# STM32C011D6Y6 register map
File version: 1.0
Registers are 32-bit, access not given, reset 0x0 unless marked. A register's access mark holds for its fields unless they carry their own. Offsets are from the block's base; [hi:lo] are bit positions; {n}, {i} and the like mark numbered series.

## SYSCFG
Base 0x40010000
Same registers: ITLINE 0x40010080
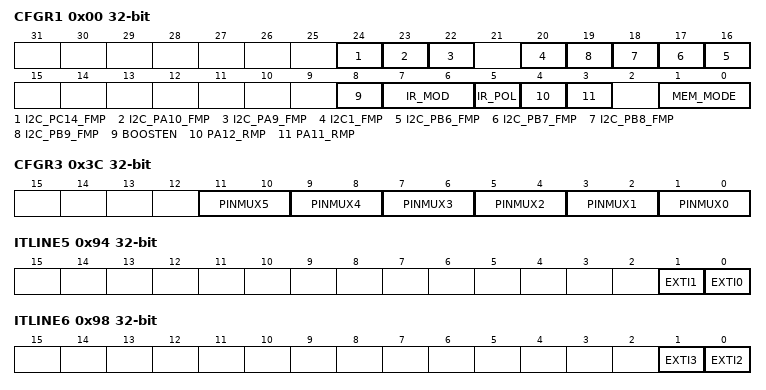
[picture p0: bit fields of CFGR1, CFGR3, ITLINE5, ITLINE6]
0x00 CFGR1
  [24] I2C_PC14_FMP, [23] I2C_PA10_FMP, [22] I2C_PA9_FMP, [20] I2C1_FMP, [n+10] I2C_PB{n}_FMP (n=6..9), [8] BOOSTEN, [7:6] IR_MOD, [5] IR_POL, [4] PA12_RMP, [3] PA11_RMP, [1:0] MEM_MODE
0x18 CFGR2
  [0] LOCUP_LOCK
0x3C CFGR3
  [2n+1:2n] PINMUX{n} (n=0..5)
0x80 ITLINE0
  [0] WWDG
0x88 ITLINE2
  [1] RTC
0x8C ITLINE3
  [1] FLASH_ITF
0x90 ITLINE4
  [0] RCC
0x94 ITLINE5
  [1] EXTI1, [0] EXTI0
0x98 ITLINE6
  [1] EXTI3, [0] EXTI2
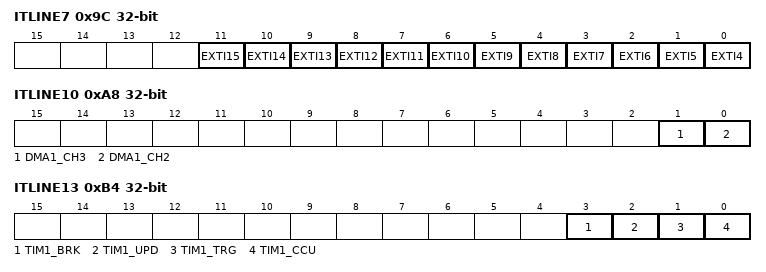
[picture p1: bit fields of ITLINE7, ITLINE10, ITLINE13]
0x9C ITLINE7
  [n-4] EXTI{n} (n=4..15)
0xA4 ITLINE9
  [0] DMA1_CH1
0xA8 ITLINE10
  [1] DMA1_CH3, [0] DMA1_CH2
0xAC ITLINE11
  [0] DMAMUX
0xB0 ITLINE12
  [0] ADC
0xB4 ITLINE13
  [3] TIM1_BRK, [2] TIM1_UPD, [1] TIM1_TRG, [0] TIM1_CCU
0xB8 ITLINE14
  [0] TIM1_CC
0xC0 ITLINE16
  [0] TIM3
0xCC ITLINE19
  [0] TIM14
0xD4 ITLINE21
  [0] TIM16
0xD8 ITLINE22
  [0] TIM17
0xDC ITLINE23
  [0] I2C1
0xE4 ITLINE25
  [0] SPI1
0xEC ITLINE27
  [0] USART1
0xF0 ITLINE28
  [0] USART2

## ADC
Base 0x40012400
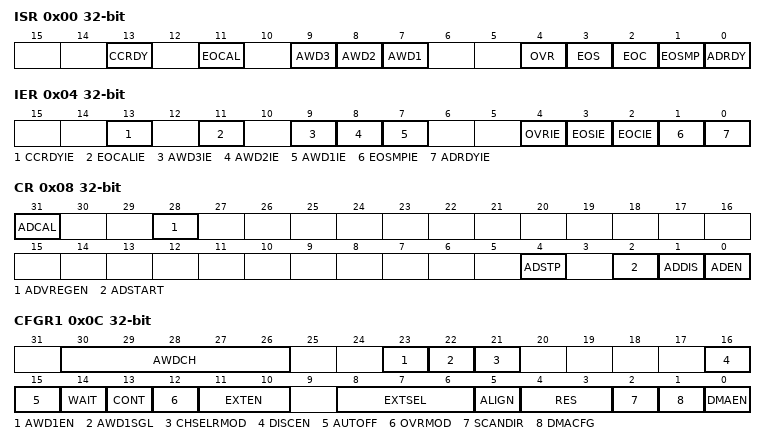
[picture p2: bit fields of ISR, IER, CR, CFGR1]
0x00 ISR
  [13] CCRDY, [11] EOCAL, [9] AWD3, [8] AWD2, [7] AWD1, [4] OVR, [3] EOS, [2] EOC, [1] EOSMP, [0] ADRDY
0x04 IER
  [13] CCRDYIE, [11] EOCALIE, [9] AWD3IE, [8] AWD2IE, [7] AWD1IE, [4] OVRIE, [3] EOSIE, [2] EOCIE, [1] EOSMPIE, [0] ADRDYIE
0x08 CR
  [31] ADCAL, [28] ADVREGEN, [4] ADSTP, [2] ADSTART, [1] ADDIS, [0] ADEN
0x0C CFGR1
  [30:26] AWDCH, [23] AWD1EN, [22] AWD1SGL, [21] CHSELRMOD, [16] DISCEN, [15] AUTOFF, [14] WAIT, [13] CONT, [12] OVRMOD, [11:10] EXTEN, [8:6] EXTSEL, [5] ALIGN, [4:3] RES, [2] SCANDIR, [1] DMACFG, [0] DMAEN
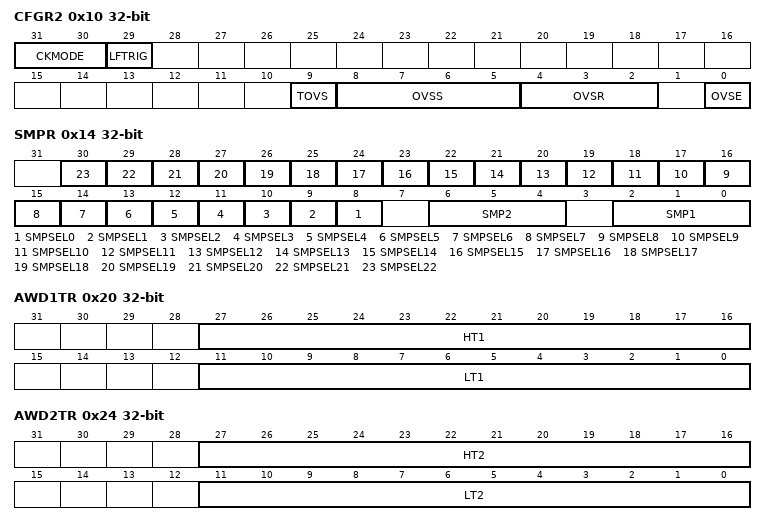
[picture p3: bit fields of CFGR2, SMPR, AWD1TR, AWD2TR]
0x10 CFGR2
  [31:30] CKMODE, [29] LFTRIG, [9] TOVS, [8:5] OVSS, [4:2] OVSR, [0] OVSE
0x14 SMPR
  [n+8] SMPSEL{n} (n=0..22), [6:4] SMP2, [2:0] SMP1
0x20 AWD1TR
  [27:16] HT1, [11:0] LT1
0x24 AWD2TR
  [27:16] HT2, [11:0] LT2
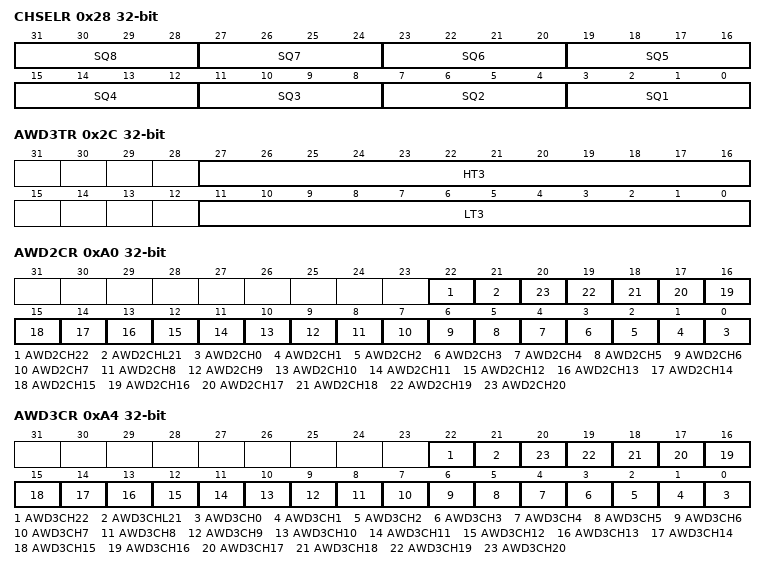
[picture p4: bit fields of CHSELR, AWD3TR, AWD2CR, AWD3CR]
0x28 CHSELR
  [4n-1:4n-4] SQ{n} (n=1..8)
0x2C AWD3TR
  [27:16] HT3, [11:0] LT3
0x40 DR
  [15:0] DATA
0xA0 AWD2CR
  [22] AWD2CH22, [21] AWD2CHL21, [n] AWD2CH{n} (n=0..20)
0xA4 AWD3CR
  [22] AWD3CH22, [21] AWD3CHL21, [n] AWD3CH{n} (n=0..20)
0xB4 CALFACT
  [6:0] CALFACT
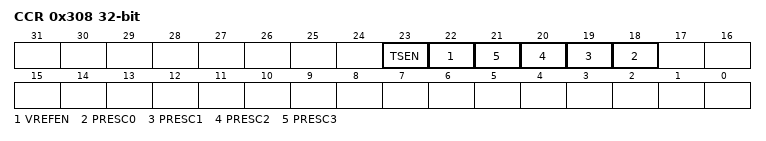
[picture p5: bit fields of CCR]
0x308 CCR
  [23] TSEN, [22] VREFEN, [n+18] PRESC{n} (n=0..3)

## TIM1
Base 0x40012C00
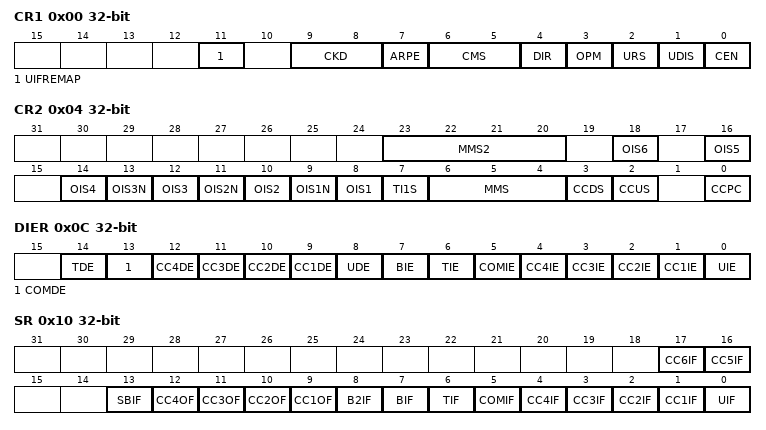
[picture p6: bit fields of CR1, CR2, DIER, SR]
0x00 CR1
  [11] UIFREMAP, [9:8] CKD, [7] ARPE, [6:5] CMS, [4] DIR, [3] OPM, [2] URS, [1] UDIS, [0] CEN
0x04 CR2
  [23:20] MMS2, [2n+6] OIS{n} (n=1..6), [13] OIS3N, [11] OIS2N, [9] OIS1N, [7] TI1S, [6:4] MMS, [3] CCDS, [2] CCUS, [0] CCPC
0x08 SMCR
  [15] ETP, [14] ECE, [13:12] ETPS, [11:8] ETF, [7] MSM, [21:4] TS, [3] OCCS, [16:0] SMS
0x0C DIER
  [14] TDE, [13] COMDE, [n+8] CC{n}DE (n=1..4), [8] UDE, [7] BIE, [6] TIE, [5] COMIE, [n] CC{n}IE (n=1..4), [0] UIE
0x10 SR
  [17] CC6IF, [16] CC5IF, [13] SBIF, [n+8] CC{n}OF (n=1..4), [8] B2IF, [7] BIF, [6] TIF, [5] COMIF, [n] CC{n}IF (n=1..4), [0] UIF
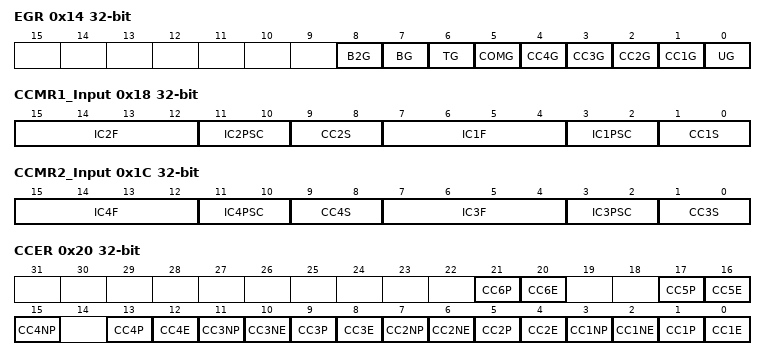
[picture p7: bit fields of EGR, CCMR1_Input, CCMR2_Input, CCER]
0x14 EGR
  [8] B2G, [7] BG, [6] TG, [5] COMG, [n] CC{n}G (n=1..4), [0] UG
0x18 CCMR1_Output
  [15] OC2CE, [24:12] OC2M, [11] OC2PE, [10] OC2FE, [9:8] CC2S, [7] OC1CE, [16:4] OC1M, [3] OC1PE, [2] OC1FE, [1:0] CC1S
0x18 CCMR1_Input
  [15:12] IC2F, [11:10] IC2PSC, [9:8] CC2S, [7:4] IC1F, [3:2] IC1PSC, [1:0] CC1S
0x1C CCMR2_Output
  [15] OC4CE, [24:12] OC4M, [11] OC4PE, [10] OC4FE, [9:8] CC4S, [7] OC3CE, [16:4] OC3M, [3] OC3PE, [2] OC3FE, [1:0] CC3S
0x1C CCMR2_Input
  [15:12] IC4F, [11:10] IC4PSC, [9:8] CC4S, [7:4] IC3F, [3:2] IC3PSC, [1:0] CC3S
0x20 CCER
  [4n-3] CC{n}P (n=1..6), [4n-4] CC{n}E (n=1..6), [4n-1] CC{n}NP (n=1..4), [10] CC3NE, [6] CC2NE, [2] CC1NE
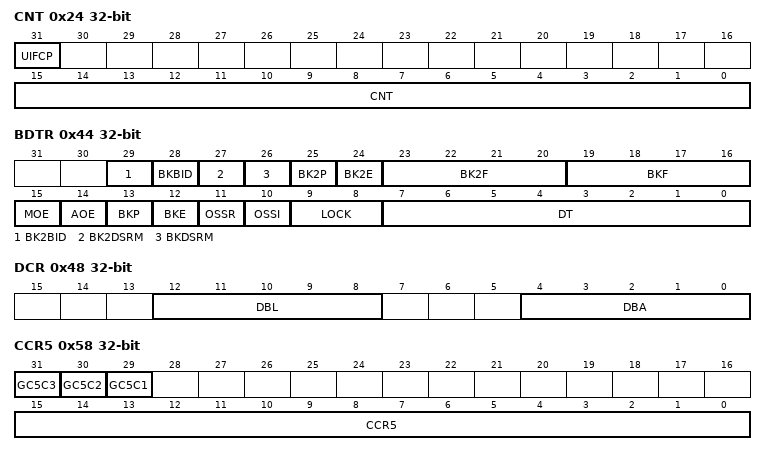
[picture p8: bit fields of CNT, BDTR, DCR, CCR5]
0x24 CNT
  [31] UIFCP, [15:0] CNT
0x28 PSC
  [15:0] PSC
0x2C ARR
  [15:0] ARR
0x30 RCR
  [15:0] REP
{0x30+4i} CCR{i} (i=1..4)
  [15:0] CCR{i}
0x44 BDTR
  [29] BK2BID, [28] BKBID, [27] BK2DSRM, [26] BKDSRM, [25] BK2P, [24] BK2E, [23:20] BK2F, [19:16] BKF, [15] MOE, [14] AOE, [13] BKP, [12] BKE, [11] OSSR, [10] OSSI, [9:8] LOCK, [7:0] DT
0x48 DCR
  [12:8] DBL, [4:0] DBA
0x4C DMAR
  [31:0] DMAB
0x54 CCMR3_Output
  [15] OC6CE, [24:12] OC6M, [11] OC6PE, [10] OC6FE, [7] OC5CE, [16:4] OC5M, [3] OC5PE, [2] OC5FE
0x58 CCR5
  [31] GC5C3, [30] GC5C2, [29] GC5C1, [15:0] CCR5
0x5C CCR6
  [15:0] CCR6
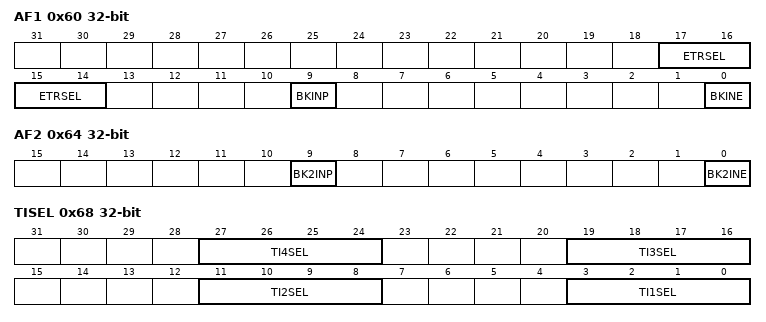
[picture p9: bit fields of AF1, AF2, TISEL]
0x60 AF1
  [17:14] ETRSEL, [9] BKINP, [0] BKINE
0x64 AF2
  [9] BK2INP, [0] BK2INE
0x68 TISEL
  [8n-5:8n-8] TI{n}SEL (n=1..4)
